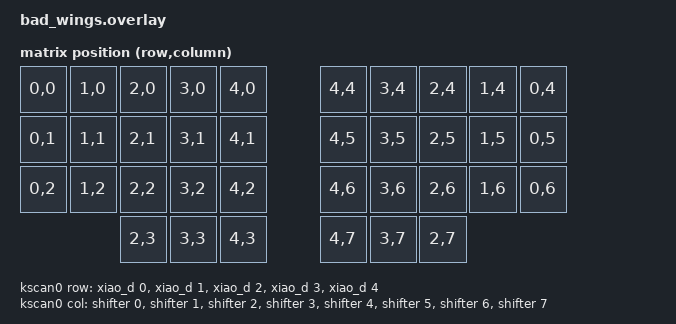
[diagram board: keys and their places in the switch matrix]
// This file was generated from a template. Edit it to match your keyboard.
// See https://zmk.dev/docs/development/hardware-integration/new-shield for more
// instructions.

#include <dt-bindings/zmk/matrix_transform.h>
#include "bad_wings-layouts.dtsi"
#include <input/processors.dtsi>

&xiao_serial { status = "disabled"; };

&xiao_spi {
    status = "okay";
    cs-gpios = <&xiao_d 6 GPIO_ACTIVE_LOW>   // 74HC595 (GP0 in QMK)
              , <&xiao_d 7 GPIO_ACTIVE_LOW>;  // Cirque (GP1 in QMK)

    shifter: 595@0 {
        compatible = "zmk,gpio-595";
        status = "okay";
        gpio-controller;
        spi-max-frequency = <200000>;
        reg = <0>;
        label = "74HC595";
        #gpio-cells = <2>;
        ngpios = <8>;
    };

    // Cirque Pinnacle trackpad (35mm) on the shared SPI bus, polled (no DR pin)
    trackpad: cirque_pinnacle@1 {
        compatible = "cirque,pinnacle";
        reg = <1>;
        status = "okay";
        spi-max-frequency = <1000000>;
        data-mode = "relative";
        sensitivity = "4x";
        primary-tap-enable;
        idle-packets-count = <0>;
        swap-xy;
    };
};

/ {
    trackpad_listener: trackpad_listener {
        compatible = "zmk,input-listener";
        status = "okay";
        device = <&trackpad>;
        // auto-activate the Mouse layer (9) on trackpad use
        input-processors = <&zip_temp_layer 9 600>;

        // Scroll layer (10): trackpad movement scrolls
        scroll {
            layers = <10>;
            input-processors = <&zip_xy_to_scroll_mapper>;
        };
    };

    chosen {
        zmk,kscan = &kscan0;
        zmk,physical-layout = &physical_layout0;
    };

    default_transform: keymap_transform_0 {
        compatible = "zmk,matrix-transform";
        columns = <8>;
        rows = <5>;

        map = <
            RC(0,0) RC(1,0) RC(2,0) RC(3,0) RC(4,0) RC(4,4) RC(3,4) RC(2,4) RC(1,4) RC(0,4)
            RC(0,1) RC(1,1) RC(2,1) RC(3,1) RC(4,1) RC(4,5) RC(3,5) RC(2,5) RC(1,5) RC(0,5)
            RC(0,2) RC(1,2) RC(2,2) RC(3,2) RC(4,2) RC(4,6) RC(3,6) RC(2,6) RC(1,6) RC(0,6)
                            RC(2,3) RC(3,3) RC(4,3) RC(4,7) RC(3,7) RC(2,7)
        >;
    };

    kscan0: kscan_0 {        
        compatible = "zmk,kscan-gpio-matrix";
        label = "KSCAN";
        diode-direction = "col2row";

        col-gpios
            = <&shifter 0 GPIO_ACTIVE_HIGH>
            , <&shifter 1 GPIO_ACTIVE_HIGH>
            , <&shifter 2 GPIO_ACTIVE_HIGH>
            , <&shifter 3 GPIO_ACTIVE_HIGH>
            , <&shifter 4 GPIO_ACTIVE_HIGH>
            , <&shifter 5 GPIO_ACTIVE_HIGH>
            , <&shifter 6 GPIO_ACTIVE_HIGH>
            , <&shifter 7 GPIO_ACTIVE_HIGH>
            ;

        row-gpios
            = <&xiao_d 0 (GPIO_ACTIVE_HIGH | GPIO_PULL_DOWN)>
            , <&xiao_d 1 (GPIO_ACTIVE_HIGH | GPIO_PULL_DOWN)>
            , <&xiao_d 2 (GPIO_ACTIVE_HIGH | GPIO_PULL_DOWN)>
            , <&xiao_d 3 (GPIO_ACTIVE_HIGH | GPIO_PULL_DOWN)>
            , <&xiao_d 4 (GPIO_ACTIVE_HIGH | GPIO_PULL_DOWN)>
            ;
    };
};
